# DA14680 register map
Vendor: Dialog; Series: DA14680; File version: 1.2
CPU: CM0 r1p0, little endian, MPU, FPU, 3 interrupt priority bits
Registers are 16-bit, read-write, reset 0x0 unless marked. A register's access mark holds for its fields unless they carry their own. Offsets are from the block's base; [hi:lo] are bit positions.

## CRG_TOP — CRG_TOP registers
Base 0x50000000
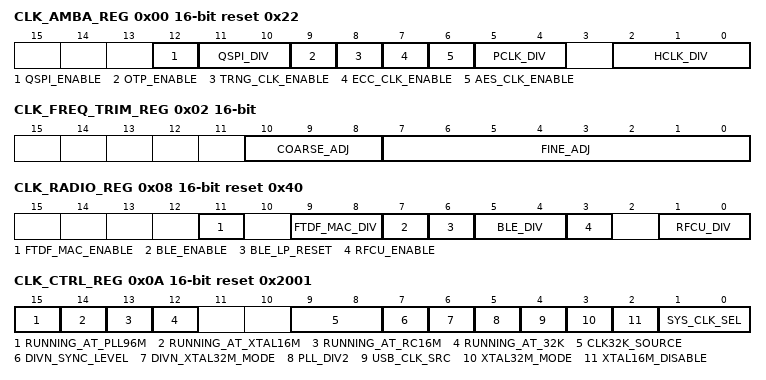
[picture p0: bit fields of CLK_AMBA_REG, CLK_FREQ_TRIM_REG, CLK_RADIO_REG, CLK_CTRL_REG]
0x00 CLK_AMBA_REG reset 0x22 — HCLK, PCLK, divider and clock gates
  [12] QSPI_ENABLE — Clock enable for QSPI controller
  [11:10] QSPI_DIV — QSPI divider 00 = divide by 1 01 = divide by 2 10 = divide by 4 11 = divide by 8
  [9] OTP_ENABLE — Clock enable for OTP controller
  [8] TRNG_CLK_ENABLE — Clock enable for TRNG block
  [7] ECC_CLK_ENABLE — Clock enable for ECC block
  [6] AES_CLK_ENABLE — Clock enable for AES crypto block
  [5:4] PCLK_DIV — APB interface clock, Cascaded with HCLK: 00 = divide hclk by 1 01 = divide hclk by 2 10 = divide hclk by 4 11 = divide hclk by 8
  [2:0] HCLK_DIV — AHB interface and microprocessor clock. Source clock divided by: 000 = divide hclk by 1 001 = divide hclk by 2 010 = divide hclk by 4 011 = divide hclk by 8 1xx = divide hclk by 16
0x02 CLK_FREQ_TRIM_REG — Xtal frequency trimming register.
  [10:8] COARSE_ADJ — Xtal frequency course trimming register. 0x0 = lowest frequency 0x7 = highest frequencyIncrement or decrement the binary value with 1. Wait approximately 200usec to allow the adjustment to settle.
  [7:0] FINE_ADJ — Xtal frequency fine trimming register.0x00 = lowest frequency 0xFF = highest frequency
0x08 CLK_RADIO_REG reset 0x40 — Radio PLL control register
  [11] FTDF_MAC_ENABLE — Enable the FTDF MAC core clocks
  [9:8] FTDF_MAC_DIV — Division factor for FTCF MAC clock, relative to the DIVN clock 00 = Divide by 1 01 = Divide by 2 10 = Divide by 4 11 = Divide by 8 It should always be set to 00.
  [7] BLE_ENABLE — Enable the BLE core clocks. When the BLE system clock is disabled, either due to the CLK_RADIO_REG[BLE_ENABLE] or due to the PMU_CTRL_REG[BLE_SLEEP], then any access to the BLE Register file will issue a hard fault to the CPU.
  [6] BLE_LP_RESET — Reset for the BLE LP timer
  [5:4] BLE_DIV — Division factor for BLE core blocks, having as reference the DIVN clock: 00 = Divide by 1 01 = Divide by 2 10 = Divide by 4 11 = Divide by 8 The programmed frequency should not be lower than 8MHz, not faster than 16MHz and not faster than the programmed CPU clock frequency. Refer also to BLE_CNTL2_REG[BLE_CLK_SEL].
  [3] RFCU_ENABLE — Enable the RF control Unit clock
  [1:0] RFCU_DIV — Division factor for RF Control Unit 0x0 = divide by 1 0x1 = divide by 2 0x2 = divide by 4 0x3 = divide by 8 The programmed frequency must be exactly 8MHz.
0x0A CLK_CTRL_REG reset 0x2001 — Clock control register
  [15] RUNNING_AT_PLL96M ro — Indicates that the PLL96MHz clock is used as clock, and may not be switched off
  [14] RUNNING_AT_XTAL16M ro — Indicates that the XTAL16M clock is used as clock, and may not be switched off
  [13] RUNNING_AT_RC16M ro — Indicates that the RC16M clock is used as clock
  [12] RUNNING_AT_32K ro — Indicates that either the RC32k or XTAL32k is being used as clock
  [9:8] CLK32K_SOURCE — Sets the clock source of the LowerPower clock '00': 32 Khz RC Oscillator '01': RCX Oscillator '10': XTAL32kHz, when using an external crystal i.c.w. the internal oscillator (set P20 and P21 to FUNC_XTAL32) '11': XTAL32kHz, when an external generator or MCU applies a square wave on P20 (set P20 to FUNC_GPIO)
  [7] DIVN_SYNC_LEVEL — Level of the RF divider to sync with in case XTAL32_MODE is set. This is used to align the internal DIVN clock XTAL@32MHz divided by 2 with the radio clock
  [6] DIVN_XTAL32M_MODE — Enables the DIVN divide-by-2, in case of a 32 MHz crystal (See also XTAL32M_MODE), to keep the DIVN clock at 16 MHz.
  [5] PLL_DIV2 — Divides the PLL clock by 2 before being used
  [4] USB_CLK_SRC — Selects the USB source clock 0 : PLL clock, divided by 2 1 : HCLK
  [3] XTAL32M_MODE — Enables dividers in the XTAL for both the RF and the BB PLL.
  [2] XTAL16M_DISABLE — Setting this bit instantaneously disables the 16 MHz crystal oscillator. This bit may not be set to '1' when "RUNNING_AT_XTAL16M is '1' to prevent deadlock. After resetting this bit, wait for XTAL16_TRIM_READY to become '1' before switching to XTAL16 clock source.
  [1:0] SYS_CLK_SEL — Selects the clock source. 0x0 : XTAL16M (check the XTAL16_TRIM_READY bit!!) 0x1 : RC16M 0x2 : The Low Power clock is used 0x3 : The PLL96Mhz is used
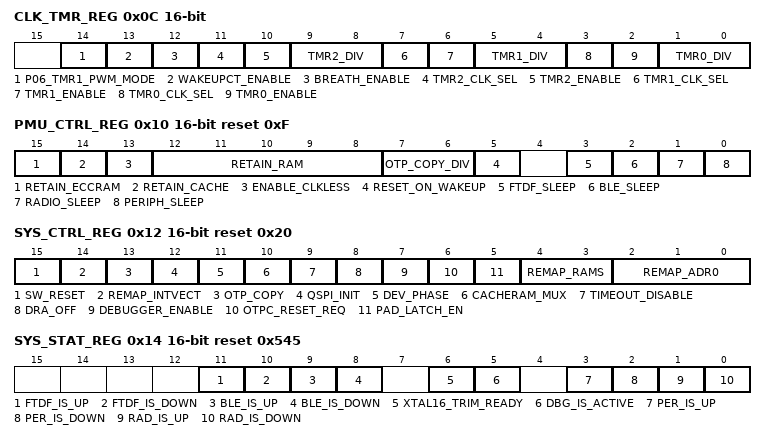
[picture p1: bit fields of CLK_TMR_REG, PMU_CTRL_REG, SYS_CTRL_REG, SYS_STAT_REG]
0x0C CLK_TMR_REG — Clock control for the timers
  [14] P06_TMR1_PWM_MODE — Maps Timer1_pwm onto P0_6, when DEBUGGER_EN = '0'. This state is preserved during deep sleep, to allow PWM5 output on the pad during deep sleep.
  [13] WAKEUPCT_ENABLE — Enables the clock
  [12] BREATH_ENABLE — Enables the clock
  [11] TMR2_CLK_SEL — Selects the clock source 1 = DIV1 clock 0 = DIVN clock
  [10] TMR2_ENABLE — Enable timer clock
  [9:8] TMR2_DIV — Division factor for Timer 0x0 = divide by 1 0x1 = divide by 2 0x2 = divide by 4 0x3 = divide by 8
  [7] TMR1_CLK_SEL — Selects the clock source 1 = DIV1 clock 0 = DIVN clock
  [6] TMR1_ENABLE — Enable timer clock
  [5:4] TMR1_DIV — Division factor for Timer 0x0 = divide by 1 0x1 = divide by 2 0x2 = divide by 4 0x3 = divide by 8
  [3] TMR0_CLK_SEL — Selects the clock source 1 = DIV1 clock 0 = DIVN clock
  [2] TMR0_ENABLE — Enable timer clock
  [1:0] TMR0_DIV — Division factor for Timer 0x0 = divide by 1 0x1 = divide by 2 0x2 = divide by 4 0x3 = divide by 8
0x10 PMU_CTRL_REG reset 0xF — Power Management Unit control register
  [15] RETAIN_ECCRAM — Selects the retainability of the ECC RAM during deep sleep. '1' is retainable, '0' is power gated
  [14] RETAIN_CACHE — Selects the retainability of the cache block during deep sleep. '1' is retainable, '0' is power gated
  [13] ENABLE_CLKLESS — Selects the clockless sleep mode. Wakeup is done asynchronously. When set to '1', the lp_clk is stopped during deep sleep, until a wakeup event (not debounced) is detected by the WAKUPCT block. When set to '0', the lp_clk continues running, so the MAC counters keep on running. This mode cannot be combined with regulated sleep, so keep SLEEP_TIMER=0 when using ENABLE_CLKLESS.
  [12:8] RETAIN_RAM — Select the retainability of the 5 system memory RAM macros during deep sleep. '1' is retainable, '0' is power gated (4) is SYSRAM5 (3) is SYSRAM4 (2) is SYSRAM3 (1) is SYSRAM2 (0) is SYSRAM1
  [7:6] OTP_COPY_DIV — Sets the HCLK division during OTP mirroring
  [5] RESET_ON_WAKEUP — Perform a Hardware Reset after waking up. Booter will be started.
  [3] FTDF_SLEEP — Put the FTDF in powerdown
  [2] BLE_SLEEP — Put the BLE in powerdown. When the BLE system clock is disabled, either due to the CLK_RADIO_REG[BLE_ENABLE] or due to the PMU_CTRL_REG[BLE_SLEEP], then any access to the BLE Register file will issue a hard fault to the CPU.
  [1] RADIO_SLEEP — Put the digital part of the radio in powerdown
  [0] PERIPH_SLEEP — Put all peripherals (I2C, UART, SPI, ADC) in powerdown
0x12 SYS_CTRL_REG reset 0x20 — System Control register
  [15] SW_RESET wo — Writing a '1' to this bit will generate a SW_RESET.
  [14] REMAP_INTVECT — 0: normal operation 1: If ARM is in address range 0 to 0xFF then the address is remapped to SYS-RAM 0x07FC.0000 to 0x07FC.00FF. This allows to put the interrupt vector table to be placed in RAM while executing from QSPI
  [13] OTP_COPY — Enables OTP to SysRAM copy action after waking up PD_SYS
  [12] QSPI_INIT — Enables QSPI initialization after wakeup
  [11] DEV_PHASE — Sets the development phase mode, used in combination with OTP_COPY No copy action to SysRAM is done when the system wakes up. For emulating startup time, the OTP_COPY bit still needs to be set.
  [10] CACHERAM_MUX — Controls accessiblity of Cache RAM: 0: the cache controller is bypassed, the cacheRAM is visible in the memory space next to the DataRAMs 1: the cache controller is enabled, the cacheRAM is not visible anymore in the memory space
  [9] TIMEOUT_DISABLE — Disables timeout in Power statemachine. By default, the statemachine continues if after 2 ms the blocks are not started up. This can be read back from ANA_STATUS_REG
  [8] DRA_OFF — Disables the DRA mode, and released the ARM reset
  [7] DEBUGGER_ENABLE — Enable the debugger. This bit is set by the booter according to the OTP header. If not set, the SWDIO and SW_CLK can be used as gpio ports.
  [6] OTPC_RESET_REQ — Reset request for the OTP controller.
  [5] PAD_LATCH_EN — Latches the control signals of the pads for state retention in powerdown mode. 0 = Control signals are retained 1 = Latch is transparant, pad can be recontrolled
  [4:3] REMAP_RAMS — Defines the sequence of the 3 first DataRAMs in the memory space. DataRAM4, DataRAM5 and potentially CacheRAM, cannot not be reshuffled. 0x0: DataRAM1, DataRAM2, DataRAM3 0x1: DataRAM2, DataRAM1, DataRAM3 0x2: DataRAM3, DataRAM1, DataRAM2 0x3: DataRAM3, DataRAM2, DataRAM1
  [2:0] REMAP_ADR0 — Controls which memory is located at address 0x0000 for execution. 0x0: ROM 0x1: OTP 0x2: FLASH 0x3: RAMS (for the exact configuration see REMAP_RAMS) 0x4: FLASH un-cached (for verification only) 0x5: OTP un-cached (for verification only) 0x6: Cache Data RAM (CACHERAM_MUX=0, for testing purposes only) Note 1: DWord (64 bits) access is not supported by the Cache Data RAM interface in mirrored mode (only 32, 16 and 8 bits). Note 2: DMA access is not supported by the Cache Data RAM interface when REMAP_ADR0=0x6.
0x14 SYS_STAT_REG reset 0x545 — System status register
  [11] FTDF_IS_UP ro — Indicates that PD_DBG is functional
  [10] FTDF_IS_DOWN ro — Indicates that PD_DBG is in power down
  [9] BLE_IS_UP ro — Indicates that PD_DBG is functional
  [8] BLE_IS_DOWN ro — Indicates that PD_DBG is in power down
  [6] XTAL16_TRIM_READY ro — Indicates that XTAL trimming mechanism is ready, i.e. the trimming equals CLK_FREQ_TRIM_REG.
  [5] DBG_IS_ACTIVE ro — Indicates that a debugger is attached.
  [3] PER_IS_UP ro — Indicates that PD_PER is functional
  [2] PER_IS_DOWN ro — Indicates that PD_PER is in power down
  [1] RAD_IS_UP ro — Indicates that PD_RAD is functional
  [0] RAD_IS_DOWN ro — Indicates that PD_RAD is in power down
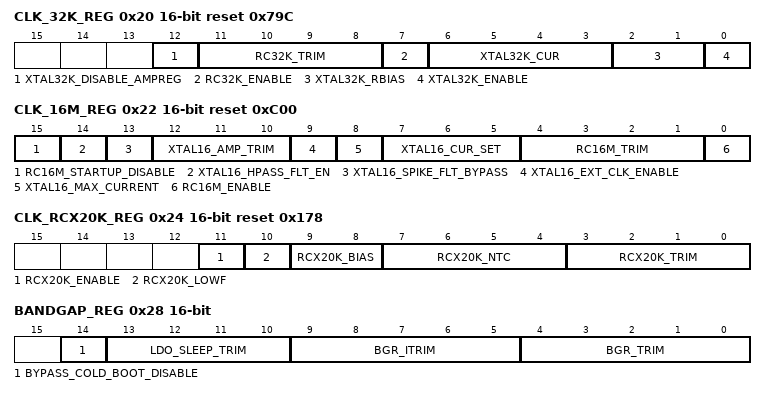
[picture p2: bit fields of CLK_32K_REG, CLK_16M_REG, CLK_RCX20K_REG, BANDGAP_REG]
0x20 CLK_32K_REG reset 0x79C — 32 kHz oscillator register
  [12] XTAL32K_DISABLE_AMPREG — Setting this bit disables the amplitude regulation of the XTAL32kHz oscillator. Set this bit to '1' for an external clock to XTAL32Kp Keep this bit '0' with a crystal between XTAL32Kp and XTAL32Km
  [11:8] RC32K_TRIM — 0000 = lowest frequency 0111 = default 1111 = highest frequency
  [7] RC32K_ENABLE — Enables the 32kHz RC oscillator
  [6:3] XTAL32K_CUR — Bias current for the 32kHz XTAL oscillator. 0000 is minimum, 1111 is maximum, 0011 is default. For each application there is an optimal setting for which the start-up behavior is optimal
  [2:1] XTAL32K_RBIAS — Setting for the bias resistor. 00 is maximum, 11 is minimum. Prefered setting will be provided by Dialog
  [0] XTAL32K_ENABLE — Enables the 32kHz XTAL oscillator
0x22 CLK_16M_REG reset 0xC00 — 16 MHz RC and xtal oscillator register
  [15] RC16M_STARTUP_DISABLE — Gates the RC16M enable from the startup block. The enable from the clksel and CLK_16M_REG[0] are not gated by this bit.
  [14] XTAL16_HPASS_FLT_EN — enables high pass filter
  [13] XTAL16_SPIKE_FLT_BYPASS — bypasses spikefilter
  [12:10] XTAL16_AMP_TRIM — sets xtal amplitude, 0 is minimum, 101 is maximum
  [9] XTAL16_EXT_CLK_ENABLE — Uses the signal on the xtal-p pin as the clock, the xtal-n pin can float.
  [8] XTAL16_MAX_CURRENT — Uses the maximum current, for testing purpose only.
  [7:5] XTAL16_CUR_SET — start-up current for the 16MHz XTAL oscillator. 000 is minimum, 110 is maximum.
  [4:1] RC16M_TRIM — 0000 = lowest frequency 1111 = highest frequency
  [0] RC16M_ENABLE — Enables the 16MHz RC oscillator
0x24 CLK_RCX20K_REG reset 0x178 — RCX-oscillator control register
  [11] RCX20K_ENABLE — Enable the RCX oscillator
  [10] RCX20K_LOWF — Extra low frequency
  [9:8] RCX20K_BIAS — Bias control
  [7:4] RCX20K_NTC — Temperature control
  [3:0] RCX20K_TRIM — 0000 = lowest frequency 0111 = default 1111 = highest frequency
0x28 BANDGAP_REG — bandgap trimming
  [14] BYPASS_COLD_BOOT_DISABLE — 0x1 -> Switch to LDO_SUPPLY_USB on vbus_available & vbus_high & wokenup (SET to 0x1 after boot) 0x0 -> Switch to LDO_SUPPLY_USB on vbus_available
  [13:10] LDO_SLEEP_TRIM — 0x4 --> 1120 mV 0x5 --> 1089 mV 0x6 --> 1058 mV 0x7 --> 1030 mV 0x0 --> 1037 mV 0x1 --> 1005 mV 0x2 --> 978 mV 0x3 --> 946 mV 0x8 --> 952 mV 0x9 --> 918 mV 0xA --> 889 mV 0xB --> 861 mV 0xC --> 862 mV 0xD --> 828 mV 0xE --> 798 mV 0xF --> 770 mV These values are from simulation and vary over corners
  [9:5] BGR_ITRIM — Current trimming for bias
  [4:0] BGR_TRIM — Trim register for bandgap
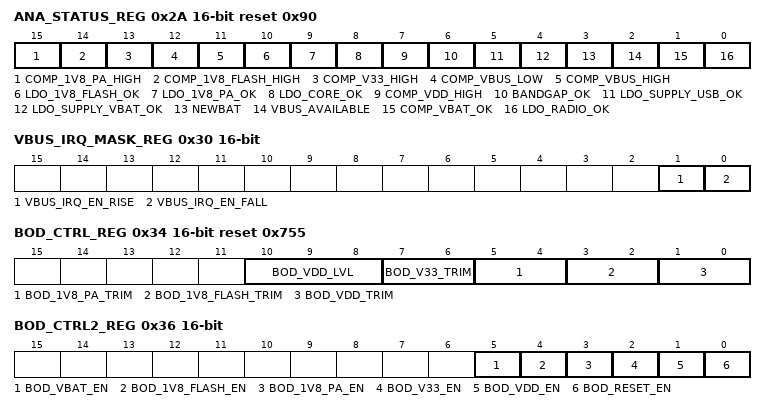
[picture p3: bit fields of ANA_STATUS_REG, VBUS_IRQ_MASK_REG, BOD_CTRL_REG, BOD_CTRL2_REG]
0x2A ANA_STATUS_REG reset 0x90 — status bit of analog (power management) circuits
  [15] COMP_1V8_PA_HIGH ro — VDD1V8P > 1.7V
  [14] COMP_1V8_FLASH_HIGH ro — VDD1V8 > 1.7V
  [13] COMP_V33_HIGH ro — V33 > 1.7V
  [12] COMP_VBUS_LOW ro — VBUS > 3.4V
  [11] COMP_VBUS_HIGH ro — VBUS > 4V
  [10] LDO_1V8_FLASH_OK ro — ldo_vdd1v8 = ok
  [9] LDO_1V8_PA_OK ro — ldo_vdd1v8P = ok
  [8] LDO_CORE_OK ro
  [7] COMP_VDD_HIGH ro — VDD > 1.13V
  [6] BANDGAP_OK ro
  [5] LDO_SUPPLY_USB_OK ro
  [4] LDO_SUPPLY_VBAT_OK ro
  [3] NEWBAT ro — new battery has been detected
  [2] VBUS_AVAILABLE ro — vbus is available (vbus > vbat)
  [1] COMP_VBAT_OK ro — vbat > 1.7V
  [0] LDO_RADIO_OK ro
0x30 VBUS_IRQ_MASK_REG — IRQ masking
  [1] VBUS_IRQ_EN_RISE — Setting this bit to '1' enables VBUS_IRQ generation when the VBUS starts to ramp above threshold
  [0] VBUS_IRQ_EN_FALL — Setting this bit to '1' enables VBUS_IRQ generation when the VBUS starts to fall below threshold
0x32 VBUS_IRQ_CLEAR_REG — Clear pending IRQ register
  [15:0] VBUS_IRQ_CLEAR — Writing any value to this register will reset the VBUS_IRQ line
0x34 BOD_CTRL_REG reset 0x755 — Brown Out Detection control register
  [10:8] BOD_VDD_LVL — VDD BOD Level; 0=700mV; 1=700mV; 3=800mV; 7=1.05V
  [7:6] BOD_V33_TRIM — V33 BOD Trimming bits
  [5:4] BOD_1V8_PA_TRIM — 1V8 PA BOD Trimming bits
  [3:2] BOD_1V8_FLASH_TRIM — 1V8 Flash BOD Trimming bits
  [1:0] BOD_VDD_TRIM — VDD BOD Trimming bits
0x36 BOD_CTRL2_REG — Brown Out Detection control register
  [5] BOD_VBAT_EN — VBAT BOD Enable
  [4] BOD_1V8_FLASH_EN — 1V8 Flash BOD Enable
  [3] BOD_1V8_PA_EN — 1V8 PA BOD Enable
  [2] BOD_V33_EN — V33 BOD Enable
  [1] BOD_VDD_EN — VDD BOD Enable
  [0] BOD_RESET_EN — Generate a chip reset on BOD event
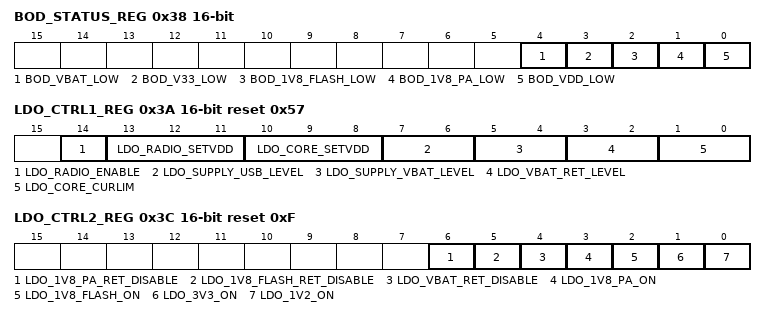
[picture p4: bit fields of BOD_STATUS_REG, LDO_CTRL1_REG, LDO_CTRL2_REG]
0x38 BOD_STATUS_REG — Brown Out Detection status register
  [4] BOD_VBAT_LOW — Indicates VBAT > VBAT_Trigger
  [3] BOD_V33_LOW — Indicates V33 > V33_Trigger
  [2] BOD_1V8_FLASH_LOW — Indicates V18_Flash > V18_Flash_Trigger
  [1] BOD_1V8_PA_LOW — Indicates V18_PA > V18_PA_Trigger
  [0] BOD_VDD_LOW — Indicates VDD > VDD_Trigger
0x3A LDO_CTRL1_REG reset 0x57 — LDO control register
  [14] LDO_RADIO_ENABLE — Enables (1) or disables (0) LDO_RADIO (V14) For fast XTAL startup, this bit may be kept to '1' during deep sleep. The LDO is switched off automatically when in deep sleep, and enabled when waking up.
  [13:11] LDO_RADIO_SETVDD — Sets the output voltage of LDO_RADIO 000 = 1.30 V 001 = 1.35 V 010 = 1.40 V 011 = 1.45 V 1XX = 1.50 V
  [10:8] LDO_CORE_SETVDD — Sets the output voltage of LDO_CORE 000 = 1.20 V 001 = 1.15 V 010 = 1.10 V 011 = 1.05 V 1XX = 1.32 V
  [7:6] LDO_SUPPLY_USB_LEVEL — Sets the output voltage of LDO_SUPPLY_USB 00 = 2.40 V 01 = 3.30 V 10 = 3.45 V 11 = 3.60 V
  [5:4] LDO_SUPPLY_VBAT_LEVEL — Sets the output voltage of LDO_SUPPLY_VBAT 00 = 2.40 V 01 = 3.30 V 10 = 3.45 V 11 = 3.60 V
  [3:2] LDO_VBAT_RET_LEVEL — Sets the output voltage of LDO_VBAT_RET 00 = 2.40 V 01 = 3.30 V 10 = 3.45 V 11 = 3.60 V
  [1:0] LDO_CORE_CURLIM — Sets the current limit of LDO_CORE 00 = Current limiter disabled 01 = 8 mA 10 = 60 mA 11 = 80 mA
0x3C LDO_CTRL2_REG reset 0xF — LDO control register
  [6] LDO_1V8_PA_RET_DISABLE — Disables (1) or enables (0) LDO_1V8_PA_RET
  [5] LDO_1V8_FLASH_RET_DISABLE — Disables (1) or enables (0) LDO_1V8_FLASH_RET
  [4] LDO_VBAT_RET_DISABLE — Disables (1) or enables (0) LDO_VBAT_RET
  [3] LDO_1V8_PA_ON — Enables (1) or disables (0) LDO_1V8_PA
  [2] LDO_1V8_FLASH_ON — Enables (1) or disables (0) LDO_1V8_FLASH
  [1] LDO_3V3_ON — Enables (1) or disables (0) LDO_SUPPLY_VBAT and LDO_SUPPLY_USB
  [0] LDO_1V2_ON — Enables (1) or disables (0) LDO_CORE
0x3E SLEEP_TIMER_REG — Timer for regulated sleep
  [15:0] SLEEP_TIMER — Defines the amount of ticks of the sleep clock between enabling the bandgap for re-charging the retention LDOs. This value depends on the load and should be calibrated on a per application basis.If set to 0, no recharging cycle will happen at all. Keep this value to 0 (no recharging) when using the clockless sleep.
0x50 XTALRDY_CTRL_REG — Control register for XTALRDY IRQ
  [7:0] XTALRDY_CNT — Number of LP cycles between the crystal is enabled, and the XTALRDY_IRQ is fired. 0x00: no interrupt
